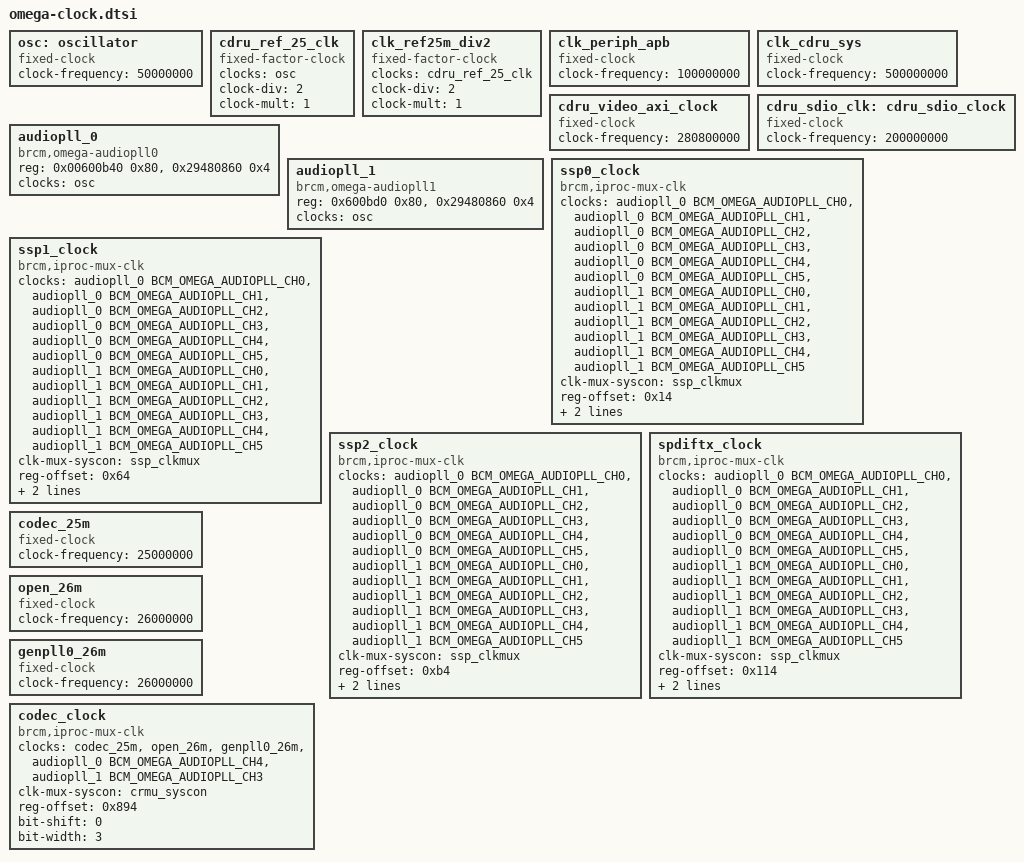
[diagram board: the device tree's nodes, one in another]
// SPDX-License-Identifier: (GPL-2.0 or BSD-3-Clause)
/*
 *  Copyright(c) 2018 Broadcom
 */

#include <dt-bindings/clock/bcm-omega.h>

	osc: oscillator {
		#clock-cells = <0>;
		compatible = "fixed-clock";
		clock-frequency = <50000000>;
	};

	cdru_ref_25_clk: cdru_ref_25_clk {
		#clock-cells = <0>;
		compatible = "fixed-factor-clock";
		clocks = <&osc>;
		clock-div = <2>;
		clock-mult = <1>;
	};

	clk_ref25m_div2: clk_ref25m_div2 {
		#clock-cells = <0>;
		compatible = "fixed-factor-clock";
		clocks = <&cdru_ref_25_clk>;
		clock-div = <2>;
		clock-mult = <1>;
	};

	clk_periph_apb: clk_periph_apb {
		#clock-cells = <0>;
		compatible = "fixed-clock";
		clock-frequency = <100000000>;
	};

	clk_cdru_sys: clk_cdru_sys {
		#clock-cells = <0>;
		compatible = "fixed-clock";
		clock-frequency = <500000000>;
	};

	cdru_video_axi_clock: cdru_video_axi_clock {
		#clock-cells = <0>;
		compatible = "fixed-clock";
		clock-frequency = <280800000>;
	};

	cdru_sdio_clk: cdru_sdio_clock {
		#clock-cells = <0>;
		compatible = "fixed-clock";
		clock-frequency = <200000000>;
	};

	audiopll_0: audiopll_0 {
		#clock-cells = <1>;
		compatible = "brcm,omega-audiopll0";
		reg = <0x00600b40 0x80>, <0x29480860 0x4>;
		clocks = <&osc>;
	};

	audiopll_1: audiopll_1 {
		#clock-cells = <1>;
		compatible = "brcm,omega-audiopll1";
		reg = <0x600bd0 0x80>, <0x29480860 0x4>;
		clocks = <&osc>;
	};

	ssp0_clock: ssp0_clock {
		#clock-cells = <0>;
		compatible = "brcm,iproc-mux-clk";
		clocks = <&audiopll_0 BCM_OMEGA_AUDIOPLL_CH0>,
			 <&audiopll_0 BCM_OMEGA_AUDIOPLL_CH1>,
			 <&audiopll_0 BCM_OMEGA_AUDIOPLL_CH2>,
			 <&audiopll_0 BCM_OMEGA_AUDIOPLL_CH3>,
			 <&audiopll_0 BCM_OMEGA_AUDIOPLL_CH4>,
			 <&audiopll_0 BCM_OMEGA_AUDIOPLL_CH5>,
			 <&audiopll_1 BCM_OMEGA_AUDIOPLL_CH0>,
			 <&audiopll_1 BCM_OMEGA_AUDIOPLL_CH1>,
			 <&audiopll_1 BCM_OMEGA_AUDIOPLL_CH2>,
			 <&audiopll_1 BCM_OMEGA_AUDIOPLL_CH3>,
			 <&audiopll_1 BCM_OMEGA_AUDIOPLL_CH4>,
			 <&audiopll_1 BCM_OMEGA_AUDIOPLL_CH5>;

		clk-mux-syscon = <&ssp_clkmux>;
		reg-offset = <0x14>;
		bit-shift = <0>;
		bit-width = <4>;
	};

	ssp1_clock: ssp1_clock {
		#clock-cells = <0>;
		compatible = "brcm,iproc-mux-clk";
		clocks = <&audiopll_0 BCM_OMEGA_AUDIOPLL_CH0>,
			 <&audiopll_0 BCM_OMEGA_AUDIOPLL_CH1>,
			 <&audiopll_0 BCM_OMEGA_AUDIOPLL_CH2>,
			 <&audiopll_0 BCM_OMEGA_AUDIOPLL_CH3>,
			 <&audiopll_0 BCM_OMEGA_AUDIOPLL_CH4>,
			 <&audiopll_0 BCM_OMEGA_AUDIOPLL_CH5>,
			 <&audiopll_1 BCM_OMEGA_AUDIOPLL_CH0>,
			 <&audiopll_1 BCM_OMEGA_AUDIOPLL_CH1>,
			 <&audiopll_1 BCM_OMEGA_AUDIOPLL_CH2>,
			 <&audiopll_1 BCM_OMEGA_AUDIOPLL_CH3>,
			 <&audiopll_1 BCM_OMEGA_AUDIOPLL_CH4>,
			 <&audiopll_1 BCM_OMEGA_AUDIOPLL_CH5>;

		clk-mux-syscon = <&ssp_clkmux>;
		reg-offset = <0x64>;
		bit-shift = <0>;
		bit-width = <4>;
	};

	ssp2_clock: ssp2_clock {
		#clock-cells = <0>;
		compatible = "brcm,iproc-mux-clk";
		clocks = <&audiopll_0 BCM_OMEGA_AUDIOPLL_CH0>,
			 <&audiopll_0 BCM_OMEGA_AUDIOPLL_CH1>,
			 <&audiopll_0 BCM_OMEGA_AUDIOPLL_CH2>,
			 <&audiopll_0 BCM_OMEGA_AUDIOPLL_CH3>,
			 <&audiopll_0 BCM_OMEGA_AUDIOPLL_CH4>,
			 <&audiopll_0 BCM_OMEGA_AUDIOPLL_CH5>,
			 <&audiopll_1 BCM_OMEGA_AUDIOPLL_CH0>,
			 <&audiopll_1 BCM_OMEGA_AUDIOPLL_CH1>,
			 <&audiopll_1 BCM_OMEGA_AUDIOPLL_CH2>,
			 <&audiopll_1 BCM_OMEGA_AUDIOPLL_CH3>,
			 <&audiopll_1 BCM_OMEGA_AUDIOPLL_CH4>,
			 <&audiopll_1 BCM_OMEGA_AUDIOPLL_CH5>;

		clk-mux-syscon = <&ssp_clkmux>;
		reg-offset = <0xb4>;
		bit-shift = <0>;
		bit-width = <4>;
	};

	spdiftx_clock: spdiftx_clock {
		#clock-cells = <0>;
		compatible = "brcm,iproc-mux-clk";
		clocks = <&audiopll_0 BCM_OMEGA_AUDIOPLL_CH0>,
			 <&audiopll_0 BCM_OMEGA_AUDIOPLL_CH1>,
			 <&audiopll_0 BCM_OMEGA_AUDIOPLL_CH2>,
			 <&audiopll_0 BCM_OMEGA_AUDIOPLL_CH3>,
			 <&audiopll_0 BCM_OMEGA_AUDIOPLL_CH4>,
			 <&audiopll_0 BCM_OMEGA_AUDIOPLL_CH5>,
			 <&audiopll_1 BCM_OMEGA_AUDIOPLL_CH0>,
			 <&audiopll_1 BCM_OMEGA_AUDIOPLL_CH1>,
			 <&audiopll_1 BCM_OMEGA_AUDIOPLL_CH2>,
			 <&audiopll_1 BCM_OMEGA_AUDIOPLL_CH3>,
			 <&audiopll_1 BCM_OMEGA_AUDIOPLL_CH4>,
			 <&audiopll_1 BCM_OMEGA_AUDIOPLL_CH5>;

		clk-mux-syscon = <&ssp_clkmux>;
		reg-offset = <0x114>;
		bit-shift = <0>;
		bit-width = <4>;
	};

	codec_25m: codec_25m {
		#clock-cells = <0>;
		compatible = "fixed-clock";
		clock-frequency = <25000000>;
	};

	open_26m: open_26m {
		#clock-cells = <0>;
		compatible = "fixed-clock";
		clock-frequency = <26000000>;
	};

	genpll0_26m: genpll0_26m {
		#clock-cells = <0>;
		compatible = "fixed-clock";
		clock-frequency = <26000000>;
	};

	codec_clock: codec_clock {
		#clock-cells = <0>;
		compatible = "brcm,iproc-mux-clk";
		clocks = <&codec_25m>,
			 <&open_26m>,
			 <&genpll0_26m>,
			 <&audiopll_0 BCM_OMEGA_AUDIOPLL_CH4>,
			 <&audiopll_1 BCM_OMEGA_AUDIOPLL_CH3>;

		clk-mux-syscon = <&crmu_syscon>;
		reg-offset = <0x894>;
		bit-shift = <0>;
		bit-width = <3>;
	};
